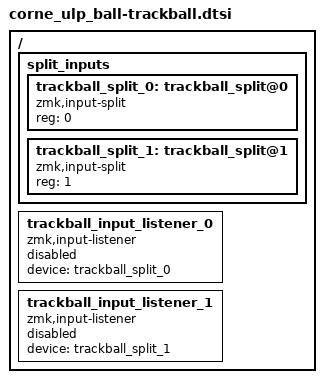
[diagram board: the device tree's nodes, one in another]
/ {
      split_inputs {
        #address-cells = <1>;
        #size-cells = <0>;

        trackball_split_0: trackball_split@0 {
            compatible = "zmk,input-split";
            reg = <0>;
        };

        trackball_split_1: trackball_split@1 {
            compatible = "zmk,input-split";
            reg = <1>;
        };
    };

    trackball_input_listener_0: trackball_input_listener_0 {
        compatible = "zmk,input-listener";
        status = "disabled";
        device = <&trackball_split_0>;
    };

    trackball_input_listener_1: trackball_input_listener_1 {
        compatible = "zmk,input-listener";
        status = "disabled";
        device = <&trackball_split_1>;
    }; 
};
